# WKUP_j7aen_wkup_ctrl_mmr0_CFG0 register map
Vendor: Texas Instruments
Registers are 32-bit, read-write, reset 0x0 unless marked. A register's access mark holds for its fields unless they carry their own. Offsets are as the file gives them; [hi:lo] are bit positions; {n}, {i} and the like mark numbered series.

## WKUP_j7aen_wkup_ctrl_mmr0_CFG0 (part 2 of 3)
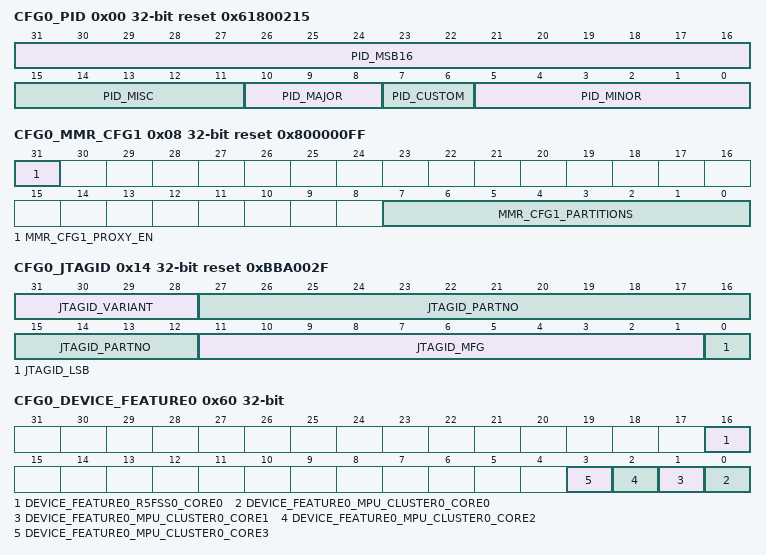
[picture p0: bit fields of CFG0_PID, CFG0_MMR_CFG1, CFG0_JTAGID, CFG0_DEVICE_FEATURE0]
0x00 CFG0_PID ro reset 0x61800215
  [31:16] PID_MSB16, [15:11] PID_MISC, [10:8] PID_MAJOR, [7:6] PID_CUSTOM, [5:0] PID_MINOR
0x08 CFG0_MMR_CFG1 ro reset 0x800000FF
  [31] MMR_CFG1_PROXY_EN — Proxy addressing activated
  [7:0] MMR_CFG1_PARTITIONS — Indicates present partitions
0x14 CFG0_JTAGID ro reset 0xBBA002F
  [31:28] JTAGID_VARIANT — Used to indicate new PGs
  [27:12] JTAGID_PARTNO — Part number for boundary scan
  [11:1] JTAGID_MFG — Indicates manufacturer
  [0] JTAGID_LSB — Always 1
0x18 CFG0_JTAG_USER_ID ro
  [31:0] JTAG_USER_ID_USERCODE — Device information
0x30 CFG0_MAIN_DEVSTAT
  [15:0] MAIN_DEVSTAT_BOOTMODE — Specifies the device Primary and Backup boot media.
0x34 CFG0_MAIN_BOOTCFG ro
  [15:0] MAIN_BOOTCFG_BOOTMODE — Specifies the device Primary and Backup boot media as latched at PORz
0x44 CFG0_BOOT_PROGRESS
  [31:0] BOOT_PROGRESS_PROGRESS — Written by ROM to indicate boot progression. Values and their meaning are determined by the ROM.
0x60 CFG0_DEVICE_FEATURE0 ro
  [16] DEVICE_FEATURE0_R5FSS0_CORE0 — Main R5FSS CPU0 Availability Field values (others are reserved): 1'b0 - NOT_AVAILABLE 1'b1 - AVAILABLE
  [n] DEVICE_FEATURE0_MPU_CLUSTER0_CORE{n} (n=0..3) — MPU Cluster0 Core {n} Availability Field values (others are reserved): 1'b0 - NOT_AVAILABLE 1'b1 - AVAILABLE
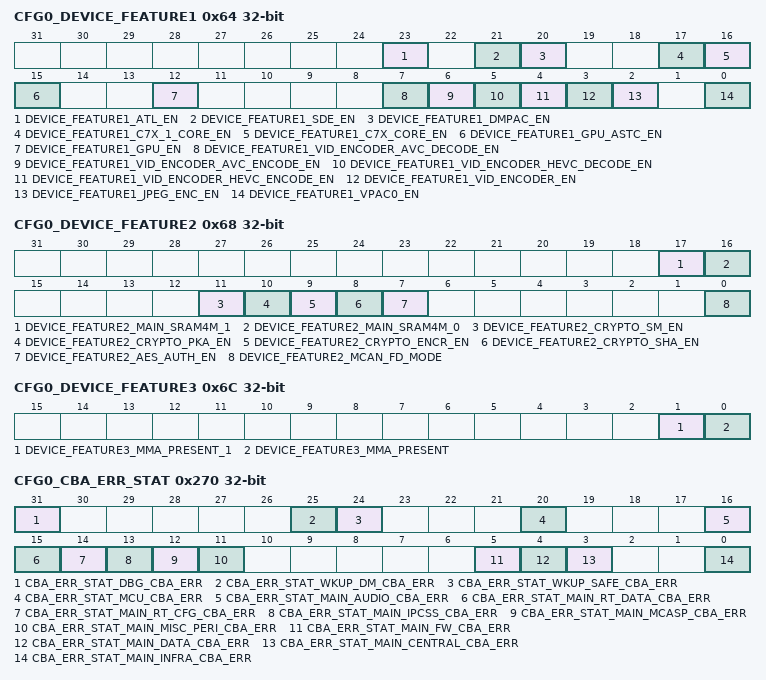
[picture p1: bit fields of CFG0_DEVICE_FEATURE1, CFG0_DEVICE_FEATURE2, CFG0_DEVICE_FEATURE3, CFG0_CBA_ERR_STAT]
0x64 CFG0_DEVICE_FEATURE1 ro
  [23] DEVICE_FEATURE1_ATL_EN — ATL Availability Field values (others are reserved): 1'b0 - NOT_AVAILABLE 1'b1 - AVAILABLE
  [21] DEVICE_FEATURE1_SDE_EN — DMPAC Stereo Disparity Engine is enabled when set Field values (others are reserved): 1'b0 - NOT_AVAILABLE 1'b1 - AVAILABLE
  [20] DEVICE_FEATURE1_DMPAC_EN — DMPAC is enabled when set Field values (others are reserved): 1'b0 - NOT_AVAILABLE 1'b1 - AVAILABLE
  [17] DEVICE_FEATURE1_C7X_1_CORE_EN — C7x1 Availability Field values (others are reserved): 1'b0 - NOT_AVAILABLE 1'b1 - AVAILABLE
  [16] DEVICE_FEATURE1_C7X_CORE_EN — C7x0 Availability Field values (others are reserved): 1'b0 - NOT_AVAILABLE 1'b1 - AVAILABLE
  [15] DEVICE_FEATURE1_GPU_ASTC_EN — GPU Adaptive Scalable Texture Compression Availability Field values (others are reserved): 1'b0 - NOT_AVAILABLE 1'b1 - AVAILABLE
  [12] DEVICE_FEATURE1_GPU_EN — GPU Availability Field values (others are reserved): 1'b0 - NOT_AVAILABLE 1'b1 - AVAILABLE
  [7] DEVICE_FEATURE1_VID_ENCODER_AVC_DECODE_EN — Video CODEC HEVC decode feature Availability Field values (others are reserved): 1'b0 - NOT_AVAILABLE 1'b1 - AVAILABLE
  [6] DEVICE_FEATURE1_VID_ENCODER_AVC_ENCODE_EN — Video CODEC HEVC encode feature Availability Field values (others are reserved): 1'b0 - NOT_AVAILABLE 1'b1 - AVAILABLE
  [5] DEVICE_FEATURE1_VID_ENCODER_HEVC_DECODE_EN — Video CODEC AVC decode feature Availability Field values (others are reserved): 1'b0 - NOT_AVAILABLE 1'b1 - AVAILABLE
  [4] DEVICE_FEATURE1_VID_ENCODER_HEVC_ENCODE_EN — Video CODEC AVC encode feature Availability Field values (others are reserved): 1'b0 - NOT_AVAILABLE 1'b1 - AVAILABLE
  [3] DEVICE_FEATURE1_VID_ENCODER_EN — Video CODEC Availability Field values (others are reserved): 1'b0 - NOT_AVAILABLE 1'b1 - AVAILABLE
  [2] DEVICE_FEATURE1_JPEG_ENC_EN — JPEG Encoder Availability Field values (others are reserved): 1'b0 - NOT_AVAILABLE 1'b1 - AVAILABLE
  [0] DEVICE_FEATURE1_VPAC0_EN — VPAC0 Availability Field values (others are reserved): 1'b0 - NOT_AVAILABLE 1'b1 - AVAILABLE
0x68 CFG0_DEVICE_FEATURE2 ro
  [17] DEVICE_FEATURE2_MAIN_SRAM4M_1 — Availability of Main SRAM 4M Bank 1 Field values (others are reserved): 1'b0 - NOT_AVAILABLE 1'b1 - AVAILABLE
  [16] DEVICE_FEATURE2_MAIN_SRAM4M_0 — Availability of Main SRAM 4M Bank 0 Field values (others are reserved): 1'b0 - NOT_AVAILABLE 1'b1 - AVAILABLE
  [11] DEVICE_FEATURE2_CRYPTO_SM_EN — SA3SS Crypto Module SM2, SM3, SM4 Availability Field values (others are reserved): 1'b0 - NOT_AVAILABLE 1'b1 - AVAILABLE
  [10] DEVICE_FEATURE2_CRYPTO_PKA_EN — SA3SS Crypto Module PKA Availability Field values (others are reserved): 1'b0 - NOT_AVAILABLE 1'b1 - AVAILABLE
  [9] DEVICE_FEATURE2_CRYPTO_ENCR_EN — SA3SS Crypto Module AES/3DES/DBRG Availability Field values (others are reserved): 1'b0 - NOT_AVAILABLE 1'b1 - AVAILABLE
  [8] DEVICE_FEATURE2_CRYPTO_SHA_EN — SA3SS Crypto Module SHA/MD5 Availability Field values (others are reserved): 1'b0 - NOT_AVAILABLE 1'b1 - AVAILABLE
  [7] DEVICE_FEATURE2_AES_AUTH_EN — AES authentication availability in FlashSS and SMS Field values (others are reserved): 1'b0 - NOT_AVAILABLE 1'b1 - AVAILABLE
  [0] DEVICE_FEATURE2_MCAN_FD_MODE — FD mode availability (applies to all MCAN instances) Field values (others are reserved): 1'b0 - NOT_AVAILABLE 1'b1 - AVAILABLE
0x6C CFG0_DEVICE_FEATURE3 ro
  [1] DEVICE_FEATURE3_MMA_PRESENT_1 — C7x1 MMA Feature Availability Field values (others are reserved): 1'b0 - NOT_AVAILABLE 1'b1 - AVAILABLE
  [0] DEVICE_FEATURE3_MMA_PRESENT — C7x0 MMA Feature Availability Field values (others are reserved): 1'b0 - NOT_AVAILABLE 1'b1 - AVAILABLE
0x78 CFG0_DEVICE_FEATURE6 ro
  [5] DEVICE_FEATURE6_SA3_UL — SA3SS domain security accelerator availability Field values (others are reserved): 1'b0 - NOT_AVAILABLE 1'b1 - AVAILABLE
0x200 CFG0_MAC_ID0
  [31:0] MAC_ID0_MACID_LO — 32 lsbs of MAC address
0x204 CFG0_MAC_ID1
  [15:0] MAC_ID1_MACID_HI — 16 msbs of MAC address
0x210 CFG0_PCI_DEVICE_ID0 reset 0xB010104C
  [31:0] PCI_DEVICE_ID0_ID0 — ROM writes 32-bit Value from Customer OTP to Here
0x214 CFG0_PCI_DEVICE_ID1 reset 0xB010104C
  [31:0] PCI_DEVICE_ID1_ID1 — ROM writes 32-bit Value from Customer OTP to Here
0x220 CFG0_USB_DEVICE_ID0 reset 0x61650451
  [31:0] USB_DEVICE_ID0_ID0 — ROM writes 32-bit Value from Customer OTP to Here
0x224 CFG0_USB_DEVICE_ID1 reset 0x61650451
  [31:0] USB_DEVICE_ID1_ID1 — ROM writes 32-bit Value from Customer OTP to Here
{0x230+4i} CFG0_GP_SW{i} ro (i=0..2)
  [31:0] GP_SW{i}_VAL — general purpose value
0x23C CFG0_GP_SW3 ro
  [3:0] GP_SW3_VAL — general purpose value
0x270 CFG0_CBA_ERR_STAT ro
  [31] CBA_ERR_STAT_DBG_CBA_ERR — Access Error from Main Debug CBASS Field values (others are reserved): 1'b0 - INACTIVE 1'b1 - ACTIVE
  [25] CBA_ERR_STAT_WKUP_DM_CBA_ERR — Access Error from Wkup Device Manager CBASS Field values (others are reserved): 1'b0 - INACTIVE 1'b1 - ACTIVE
  [24] CBA_ERR_STAT_WKUP_SAFE_CBA_ERR — Access Error from Wkup Safe CBASS Field values (others are reserved): 1'b0 - INACTIVE 1'b1 - ACTIVE
  [20] CBA_ERR_STAT_MCU_CBA_ERR — Access Error from MCU CBASS Field values (others are reserved): 1'b0 - INACTIVE 1'b1 - ACTIVE
  [16] CBA_ERR_STAT_MAIN_AUDIO_CBA_ERR — Access Error from Main Audio CBASS Field values (others are reserved): 1'b0 - INACTIVE 1'b1 - ACTIVE
  [15] CBA_ERR_STAT_MAIN_RT_DATA_CBA_ERR — Access Error from Main RT DATA CBASS Field values (others are reserved): 1'b0 - INACTIVE 1'b1 - ACTIVE
  [14] CBA_ERR_STAT_MAIN_RT_CFG_CBA_ERR — Access Error from Main RT CFG CBASS Field values (others are reserved): 1'b0 - INACTIVE 1'b1 - ACTIVE
  [13] CBA_ERR_STAT_MAIN_IPCSS_CBA_ERR — Access Error from Main IPCSS CBASS Field values (others are reserved): 1'b0 - INACTIVE 1'b1 - ACTIVE
  [12] CBA_ERR_STAT_MAIN_MCASP_CBA_ERR — Access Error from Main McASP CBASS Field values (others are reserved): 1'b0 - INACTIVE 1'b1 - ACTIVE
  [11] CBA_ERR_STAT_MAIN_MISC_PERI_CBA_ERR — Access Errror from Main Misc. Peripheral CBASS Field values (others are reserved): 1'b0 - INACTIVE 1'b1 - ACTIVE
  [5] CBA_ERR_STAT_MAIN_FW_CBA_ERR — Access Error from Main Firewall CBASS Field values (others are reserved): 1'b0 - INACTIVE 1'b1 - ACTIVE
  [4] CBA_ERR_STAT_MAIN_DATA_CBA_ERR — Access Error from Main Data CBASS Field values (others are reserved): 1'b0 - INACTIVE 1'b1 - ACTIVE
  [3] CBA_ERR_STAT_MAIN_CENTRAL_CBA_ERR — Access Error from Main Central CBASS Field values (others are reserved): 1'b0 - INACTIVE 1'b1 - ACTIVE
  [0] CBA_ERR_STAT_MAIN_INFRA_CBA_ERR — Access Error from Main Infrastructure CBASS Field values (others are reserved): 1'b0 - INACTIVE 1'b1 - ACTIVE
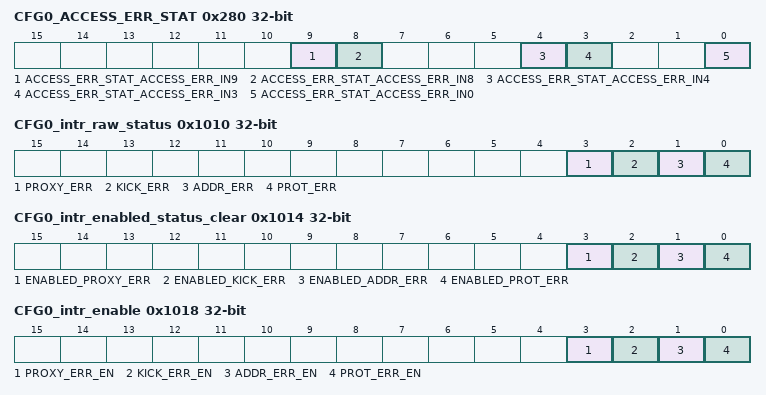
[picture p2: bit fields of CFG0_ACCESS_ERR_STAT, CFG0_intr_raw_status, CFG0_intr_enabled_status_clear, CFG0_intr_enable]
0x280 CFG0_ACCESS_ERR_STAT ro
  [9] ACCESS_ERR_STAT_ACCESS_ERR_IN9 — Access Error Detected in MCU PadCfg MMR Field values (others are reserved): 1'b0 - INACTIVE 1'b1 - ACTIVE
  [8] ACCESS_ERR_STAT_ACCESS_ERR_IN8 — Access Error Detected in MCU Ctrl MMR Field values (others are reserved): 1'b0 - INACTIVE 1'b1 - ACTIVE
  [4] ACCESS_ERR_STAT_ACCESS_ERR_IN4 — Access Error Detected in MAIN PadCfg MMR Field values (others are reserved): 1'b0 - INACTIVE 1'b1 - ACTIVE
  [3] ACCESS_ERR_STAT_ACCESS_ERR_IN3 — Access Error Detected in MAIN Ctrl MMR Field values (others are reserved): 1'b0 - INACTIVE 1'b1 - ACTIVE
  [0] ACCESS_ERR_STAT_ACCESS_ERR_IN0 — Access Error Detected in WKUP Ctrl MMR Field values (others are reserved): 1'b0 - INACTIVE 1'b1 - ACTIVE
{0x1008+0x4000*i} CFG0_LOCK{i}_KICK0 (i=0..7)
  [31:0] LOCK{i}_KICK0 — - KICK0 component
{0x100C+0x4000*i} CFG0_LOCK{i}_KICK1 (i=0..7)
  [31:0] LOCK{i}_KICK1 — - KICK1 component
0x1010 CFG0_intr_raw_status access not given
  [3] PROXY_ERR — Proxy0 access violation error. Raw status is read. Write a 1 to set the status. Writing a 0 has no effect. (access R/W1TS)
  [2] KICK_ERR — Kick access violation error. Raw status is read. Write a 1 to set the status. Writing a 0 has no effect. (access R/W1TS)
  [1] ADDR_ERR — Addressing violation error. Raw status is read. Write a 1 to set the status. Writing a 0 has no effect. (access R/W1TS)
  [0] PROT_ERR — Protection violation error. Raw status is read. Write a 1 to set the status. Writing a 0 has no effect. (access R/W1TS)
0x1014 CFG0_intr_enabled_status_clear access not given
  [3] ENABLED_PROXY_ERR — Proxy0 access violation error. Enabled status is read. Write a 1 to clear the status. Writing a 0 has no effect. (access R/W1TC)
  [2] ENABLED_KICK_ERR — Kick access violation error. Enabled status is read. Write a 1 to clear the status. Writing a 0 has no effect. (access R/W1TC)
  [1] ENABLED_ADDR_ERR — Addressing violation error. Enabled status is read. Write a 1 to clear the status. Writing a 0 has no effect. (access R/W1TC)
  [0] ENABLED_PROT_ERR — Protection violation error. Enabled status is read. Write a 1 to clear the status. Writing a 0 has no effect. (access R/W1TC)
0x1018 CFG0_intr_enable access not given
  [3] PROXY_ERR_EN — Proxy0 access violation error enable. Write a 1 to set the enable. Writing a 0 has no effect. (access R/W1TS)
  [2] KICK_ERR_EN — Kick access violation error enable. Write a 1 to set the enable. Writing a 0 has no effect. (access R/W1TS)
  [1] ADDR_ERR_EN — Addressing violation error enable. Write a 1 to set the enable. Writing a 0 has no effect. (access R/W1TS)
  [0] PROT_ERR_EN — Protection violation error enable. Write a 1 to set the enable. Writing a 0 has no effect. (access R/W1TS)
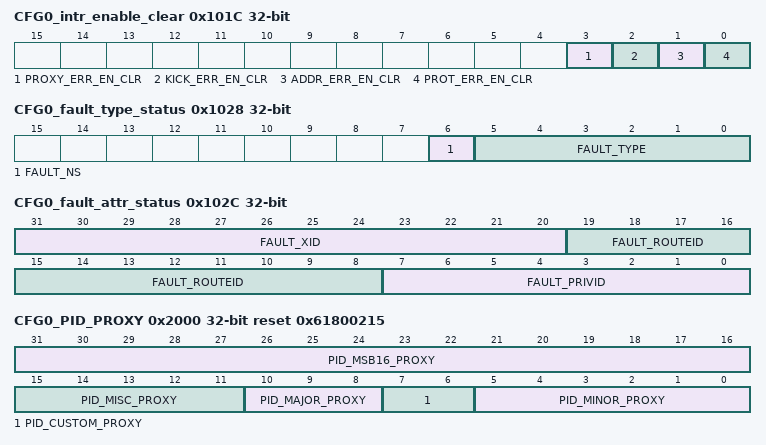
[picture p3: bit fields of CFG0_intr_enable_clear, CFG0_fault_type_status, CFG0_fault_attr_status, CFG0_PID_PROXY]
0x101C CFG0_intr_enable_clear access not given
  [3] PROXY_ERR_EN_CLR — Proxy0 access violation error enable clear. Write a 1 to clear the enable. Writing a 0 has no effect. (access R/W1TC)
  [2] KICK_ERR_EN_CLR — Kick access violation error enable clear. Write a 1 to clear the enable. Writing a 0 has no effect. (access R/W1TC)
  [1] ADDR_ERR_EN_CLR — Addressing violation error enable clear. Write a 1 to clear the enable. Writing a 0 has no effect. (access R/W1TC)
  [0] PROT_ERR_EN_CLR — Protection violation error enable clear. Write a 1 to clear the enable. Writing a 0 has no effect. (access R/W1TC)
0x1020 CFG0_eoi
  [7:0] EOI_VECTOR — EOI vector value. Write this with interrupt distribution value in the chip.
0x1024 CFG0_fault_address ro
  [31:0] FAULT_ADDR — Fault Address.
0x1028 CFG0_fault_type_status ro
  [6] FAULT_NS — Non-secure access.
  [5:0] FAULT_TYPE — Fault Type 10_0000 = Supervisor read fault - priv = 1 dir = 1 dtype != 1 01_0000 = Supervisor write fault - priv = 1 dir = 0 00_1000 = Supervisor execute fault - priv = 1 dir = 1 dtype = 1 00_0100 = User read fault - priv = 0 dir = 1 dtype = 1 00_0010 = User write fault - priv = 0 dir = 0 00_0001 = User execute fault - priv = 0 dir = 1 dtype = 1 00_0000 = No fault
0x102C CFG0_fault_attr_status ro
  [31:20] FAULT_XID — XID.
  [19:8] FAULT_ROUTEID — Route ID.
  [7:0] FAULT_PRIVID — Privilege ID.
0x1030 CFG0_fault_clear wo
  [0] FAULT_CLR — Fault clear. Writing a 1 clears the current fault. Writing a 0 has no effect.
{0x1100+4i} CFG0_CLAIMREG_P0_R{i}_READONLY ro (i=0..6)
  [31:0] CLAIMREG_P0_R{i}_READONLY — Claim bits for Partition 0
0x2000 CFG0_PID_PROXY ro reset 0x61800215
  [31:16] PID_MSB16_PROXY, [15:11] PID_MISC_PROXY, [10:8] PID_MAJOR_PROXY, [7:6] PID_CUSTOM_PROXY, [5:0] PID_MINOR_PROXY
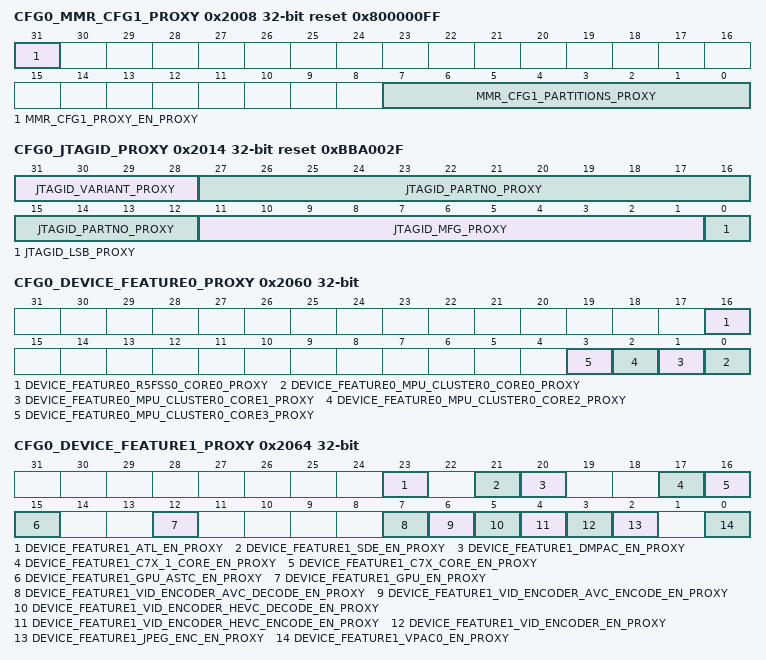
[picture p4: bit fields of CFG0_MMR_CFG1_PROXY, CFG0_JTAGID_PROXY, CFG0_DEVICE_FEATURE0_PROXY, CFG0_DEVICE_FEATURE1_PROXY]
0x2008 CFG0_MMR_CFG1_PROXY ro reset 0x800000FF
  [31] MMR_CFG1_PROXY_EN_PROXY — Proxy addressing activated
  [7:0] MMR_CFG1_PARTITIONS_PROXY — Indicates present partitions
0x2014 CFG0_JTAGID_PROXY ro reset 0xBBA002F
  [31:28] JTAGID_VARIANT_PROXY — Used to indicate new PGs
  [27:12] JTAGID_PARTNO_PROXY — Part number for boundary scan
  [11:1] JTAGID_MFG_PROXY — Indicates manufacturer
  [0] JTAGID_LSB_PROXY — Always 1
0x2018 CFG0_JTAG_USER_ID_PROXY ro
  [31:0] JTAG_USER_ID_USERCODE_PROXY — Device information
0x2030 CFG0_MAIN_DEVSTAT_PROXY
  [15:0] MAIN_DEVSTAT_BOOTMODE_PROXY — Specifies the device Primary and Backup boot media.
0x2034 CFG0_MAIN_BOOTCFG_PROXY ro
  [15:0] MAIN_BOOTCFG_BOOTMODE_PROXY — Specifies the device Primary and Backup boot media as latched at PORz
0x2044 CFG0_BOOT_PROGRESS_PROXY
  [31:0] BOOT_PROGRESS_PROGRESS_PROXY — Written by ROM to indicate boot progression. Values and their meaning are determined by the ROM.
0x2060 CFG0_DEVICE_FEATURE0_PROXY ro
  [16] DEVICE_FEATURE0_R5FSS0_CORE0_PROXY — Main R5FSS CPU0 Availability Field values (others are reserved): 1'b0 - NOT_AVAILABLE 1'b1 - AVAILABLE
  [n] DEVICE_FEATURE0_MPU_CLUSTER0_CORE{n}_PROXY (n=0..3) — MPU Cluster0 Core {n} Availability Field values (others are reserved): 1'b0 - NOT_AVAILABLE 1'b1 - AVAILABLE
0x2064 CFG0_DEVICE_FEATURE1_PROXY ro
  [23] DEVICE_FEATURE1_ATL_EN_PROXY — ATL Availability Field values (others are reserved): 1'b0 - NOT_AVAILABLE 1'b1 - AVAILABLE
  [21] DEVICE_FEATURE1_SDE_EN_PROXY — DMPAC Stereo Disparity Engine is enabled when set Field values (others are reserved): 1'b0 - NOT_AVAILABLE 1'b1 - AVAILABLE
  [20] DEVICE_FEATURE1_DMPAC_EN_PROXY — DMPAC is enabled when set Field values (others are reserved): 1'b0 - NOT_AVAILABLE 1'b1 - AVAILABLE
  [17] DEVICE_FEATURE1_C7X_1_CORE_EN_PROXY — C7x1 Availability Field values (others are reserved): 1'b0 - NOT_AVAILABLE 1'b1 - AVAILABLE
  [16] DEVICE_FEATURE1_C7X_CORE_EN_PROXY — C7x0 Availability Field values (others are reserved): 1'b0 - NOT_AVAILABLE 1'b1 - AVAILABLE
  [15] DEVICE_FEATURE1_GPU_ASTC_EN_PROXY — GPU Adaptive Scalable Texture Compression Availability Field values (others are reserved): 1'b0 - NOT_AVAILABLE 1'b1 - AVAILABLE
  [12] DEVICE_FEATURE1_GPU_EN_PROXY — GPU Availability Field values (others are reserved): 1'b0 - NOT_AVAILABLE 1'b1 - AVAILABLE
  [7] DEVICE_FEATURE1_VID_ENCODER_AVC_DECODE_EN_PROXY — Video CODEC HEVC decode feature Availability Field values (others are reserved): 1'b0 - NOT_AVAILABLE 1'b1 - AVAILABLE
  [6] DEVICE_FEATURE1_VID_ENCODER_AVC_ENCODE_EN_PROXY — Video CODEC HEVC encode feature Availability Field values (others are reserved): 1'b0 - NOT_AVAILABLE 1'b1 - AVAILABLE
  [5] DEVICE_FEATURE1_VID_ENCODER_HEVC_DECODE_EN_PROXY — Video CODEC AVC decode feature Availability Field values (others are reserved): 1'b0 - NOT_AVAILABLE 1'b1 - AVAILABLE
  [4] DEVICE_FEATURE1_VID_ENCODER_HEVC_ENCODE_EN_PROXY — Video CODEC AVC encode feature Availability Field values (others are reserved): 1'b0 - NOT_AVAILABLE 1'b1 - AVAILABLE
  [3] DEVICE_FEATURE1_VID_ENCODER_EN_PROXY — Video CODEC Availability Field values (others are reserved): 1'b0 - NOT_AVAILABLE 1'b1 - AVAILABLE
  [2] DEVICE_FEATURE1_JPEG_ENC_EN_PROXY — JPEG Encoder Availability Field values (others are reserved): 1'b0 - NOT_AVAILABLE 1'b1 - AVAILABLE
  [0] DEVICE_FEATURE1_VPAC0_EN_PROXY — VPAC0 Availability Field values (others are reserved): 1'b0 - NOT_AVAILABLE 1'b1 - AVAILABLE
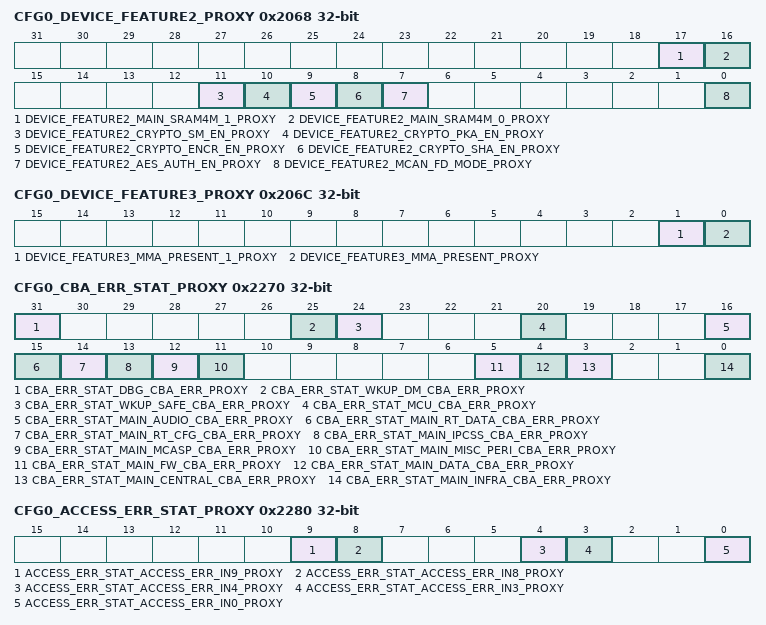
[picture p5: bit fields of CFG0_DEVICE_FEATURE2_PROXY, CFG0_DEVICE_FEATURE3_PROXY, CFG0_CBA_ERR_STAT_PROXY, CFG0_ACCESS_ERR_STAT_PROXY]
0x2068 CFG0_DEVICE_FEATURE2_PROXY ro
  [17] DEVICE_FEATURE2_MAIN_SRAM4M_1_PROXY — Availability of Main SRAM 4M Bank 1 Field values (others are reserved): 1'b0 - NOT_AVAILABLE 1'b1 - AVAILABLE
  [16] DEVICE_FEATURE2_MAIN_SRAM4M_0_PROXY — Availability of Main SRAM 4M Bank 0 Field values (others are reserved): 1'b0 - NOT_AVAILABLE 1'b1 - AVAILABLE
  [11] DEVICE_FEATURE2_CRYPTO_SM_EN_PROXY — SA3SS Crypto Module SM2, SM3, SM4 Availability Field values (others are reserved): 1'b0 - NOT_AVAILABLE 1'b1 - AVAILABLE
  [10] DEVICE_FEATURE2_CRYPTO_PKA_EN_PROXY — SA3SS Crypto Module PKA Availability Field values (others are reserved): 1'b0 - NOT_AVAILABLE 1'b1 - AVAILABLE
  [9] DEVICE_FEATURE2_CRYPTO_ENCR_EN_PROXY — SA3SS Crypto Module AES/3DES/DBRG Availability Field values (others are reserved): 1'b0 - NOT_AVAILABLE 1'b1 - AVAILABLE
  [8] DEVICE_FEATURE2_CRYPTO_SHA_EN_PROXY — SA3SS Crypto Module SHA/MD5 Availability Field values (others are reserved): 1'b0 - NOT_AVAILABLE 1'b1 - AVAILABLE
  [7] DEVICE_FEATURE2_AES_AUTH_EN_PROXY — AES authentication availability in FlashSS and SMS Field values (others are reserved): 1'b0 - NOT_AVAILABLE 1'b1 - AVAILABLE
  [0] DEVICE_FEATURE2_MCAN_FD_MODE_PROXY — FD mode availability (applies to all MCAN instances) Field values (others are reserved): 1'b0 - NOT_AVAILABLE 1'b1 - AVAILABLE
0x206C CFG0_DEVICE_FEATURE3_PROXY ro
  [1] DEVICE_FEATURE3_MMA_PRESENT_1_PROXY — C7x1 MMA Feature Availability Field values (others are reserved): 1'b0 - NOT_AVAILABLE 1'b1 - AVAILABLE
  [0] DEVICE_FEATURE3_MMA_PRESENT_PROXY — C7x0 MMA Feature Availability Field values (others are reserved): 1'b0 - NOT_AVAILABLE 1'b1 - AVAILABLE
0x2078 CFG0_DEVICE_FEATURE6_PROXY ro
  [5] DEVICE_FEATURE6_SA3_UL_PROXY — SA3SS domain security accelerator availability Field values (others are reserved): 1'b0 - NOT_AVAILABLE 1'b1 - AVAILABLE
0x2200 CFG0_MAC_ID0_PROXY
  [31:0] MAC_ID0_MACID_LO_PROXY — 32 lsbs of MAC address
0x2204 CFG0_MAC_ID1_PROXY
  [15:0] MAC_ID1_MACID_HI_PROXY — 16 msbs of MAC address
0x2210 CFG0_PCI_DEVICE_ID0_PROXY reset 0xB010104C
  [31:0] PCI_DEVICE_ID0_ID0_PROXY — ROM writes 32-bit Value from Customer OTP to Here
0x2214 CFG0_PCI_DEVICE_ID1_PROXY reset 0xB010104C
  [31:0] PCI_DEVICE_ID1_ID1_PROXY — ROM writes 32-bit Value from Customer OTP to Here
0x2220 CFG0_USB_DEVICE_ID0_PROXY reset 0x61650451
  [31:0] USB_DEVICE_ID0_ID0_PROXY — ROM writes 32-bit Value from Customer OTP to Here
0x2224 CFG0_USB_DEVICE_ID1_PROXY reset 0x61650451
  [31:0] USB_DEVICE_ID1_ID1_PROXY — ROM writes 32-bit Value from Customer OTP to Here
{0x2230+4i} CFG0_GP_SW{i}_PROXY ro (i=0..2)
  [31:0] GP_SW{i}_VAL_PROXY — general purpose value
0x223C CFG0_GP_SW3_PROXY ro
  [3:0] GP_SW3_VAL_PROXY — general purpose value
0x2270 CFG0_CBA_ERR_STAT_PROXY ro
  [31] CBA_ERR_STAT_DBG_CBA_ERR_PROXY — Access Error from Main Debug CBASS Field values (others are reserved): 1'b0 - INACTIVE 1'b1 - ACTIVE
  [25] CBA_ERR_STAT_WKUP_DM_CBA_ERR_PROXY — Access Error from Wkup Device Manager CBASS Field values (others are reserved): 1'b0 - INACTIVE 1'b1 - ACTIVE
  [24] CBA_ERR_STAT_WKUP_SAFE_CBA_ERR_PROXY — Access Error from Wkup Safe CBASS Field values (others are reserved): 1'b0 - INACTIVE 1'b1 - ACTIVE
  [20] CBA_ERR_STAT_MCU_CBA_ERR_PROXY — Access Error from MCU CBASS Field values (others are reserved): 1'b0 - INACTIVE 1'b1 - ACTIVE
  [16] CBA_ERR_STAT_MAIN_AUDIO_CBA_ERR_PROXY — Access Error from Main Audio CBASS Field values (others are reserved): 1'b0 - INACTIVE 1'b1 - ACTIVE
  [15] CBA_ERR_STAT_MAIN_RT_DATA_CBA_ERR_PROXY — Access Error from Main RT DATA CBASS Field values (others are reserved): 1'b0 - INACTIVE 1'b1 - ACTIVE
  [14] CBA_ERR_STAT_MAIN_RT_CFG_CBA_ERR_PROXY — Access Error from Main RT CFG CBASS Field values (others are reserved): 1'b0 - INACTIVE 1'b1 - ACTIVE
  [13] CBA_ERR_STAT_MAIN_IPCSS_CBA_ERR_PROXY — Access Error from Main IPCSS CBASS Field values (others are reserved): 1'b0 - INACTIVE 1'b1 - ACTIVE
  [12] CBA_ERR_STAT_MAIN_MCASP_CBA_ERR_PROXY — Access Error from Main McASP CBASS Field values (others are reserved): 1'b0 - INACTIVE 1'b1 - ACTIVE
  [11] CBA_ERR_STAT_MAIN_MISC_PERI_CBA_ERR_PROXY — Access Errror from Main Misc. Peripheral CBASS Field values (others are reserved): 1'b0 - INACTIVE 1'b1 - ACTIVE
  [5] CBA_ERR_STAT_MAIN_FW_CBA_ERR_PROXY — Access Error from Main Firewall CBASS Field values (others are reserved): 1'b0 - INACTIVE 1'b1 - ACTIVE
  [4] CBA_ERR_STAT_MAIN_DATA_CBA_ERR_PROXY — Access Error from Main Data CBASS Field values (others are reserved): 1'b0 - INACTIVE 1'b1 - ACTIVE
  [3] CBA_ERR_STAT_MAIN_CENTRAL_CBA_ERR_PROXY — Access Error from Main Central CBASS Field values (others are reserved): 1'b0 - INACTIVE 1'b1 - ACTIVE
  [0] CBA_ERR_STAT_MAIN_INFRA_CBA_ERR_PROXY — Access Error from Main Infrastructure CBASS Field values (others are reserved): 1'b0 - INACTIVE 1'b1 - ACTIVE
0x2280 CFG0_ACCESS_ERR_STAT_PROXY ro
  [9] ACCESS_ERR_STAT_ACCESS_ERR_IN9_PROXY — Access Error Detected in MCU PadCfg MMR Field values (others are reserved): 1'b0 - INACTIVE 1'b1 - ACTIVE
  [8] ACCESS_ERR_STAT_ACCESS_ERR_IN8_PROXY — Access Error Detected in MCU Ctrl MMR Field values (others are reserved): 1'b0 - INACTIVE 1'b1 - ACTIVE
  [4] ACCESS_ERR_STAT_ACCESS_ERR_IN4_PROXY — Access Error Detected in MAIN PadCfg MMR Field values (others are reserved): 1'b0 - INACTIVE 1'b1 - ACTIVE
  [3] ACCESS_ERR_STAT_ACCESS_ERR_IN3_PROXY — Access Error Detected in MAIN Ctrl MMR Field values (others are reserved): 1'b0 - INACTIVE 1'b1 - ACTIVE
  [0] ACCESS_ERR_STAT_ACCESS_ERR_IN0_PROXY — Access Error Detected in WKUP Ctrl MMR Field values (others are reserved): 1'b0 - INACTIVE 1'b1 - ACTIVE
{0x3008+0x4000*i} CFG0_LOCK{i}_KICK0_PROXY (i=0..7)
  [31:0] LOCK{i}_KICK0_PROXY — - KICK0 component
{0x300C+0x4000*i} CFG0_LOCK{i}_KICK1_PROXY (i=0..7)
  [31:0] LOCK{i}_KICK1_PROXY — - KICK1 component
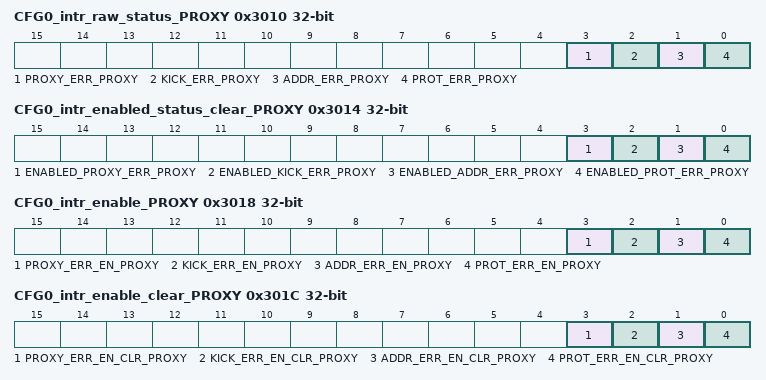
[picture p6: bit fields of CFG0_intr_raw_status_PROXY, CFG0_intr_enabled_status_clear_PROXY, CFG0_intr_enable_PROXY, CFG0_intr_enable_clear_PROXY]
0x3010 CFG0_intr_raw_status_PROXY access not given
  [3] PROXY_ERR_PROXY — Proxy0 access violation error. Raw status is read. Write a 1 to set the status. Writing a 0 has no effect. (access R/W1TS)
  [2] KICK_ERR_PROXY — Kick access violation error. Raw status is read. Write a 1 to set the status. Writing a 0 has no effect. (access R/W1TS)
  [1] ADDR_ERR_PROXY — Addressing violation error. Raw status is read. Write a 1 to set the status. Writing a 0 has no effect. (access R/W1TS)
  [0] PROT_ERR_PROXY — Protection violation error. Raw status is read. Write a 1 to set the status. Writing a 0 has no effect. (access R/W1TS)
0x3014 CFG0_intr_enabled_status_clear_PROXY access not given
  [3] ENABLED_PROXY_ERR_PROXY — Proxy0 access violation error. Enabled status is read. Write a 1 to clear the status. Writing a 0 has no effect. (access R/W1TC)
  [2] ENABLED_KICK_ERR_PROXY — Kick access violation error. Enabled status is read. Write a 1 to clear the status. Writing a 0 has no effect. (access R/W1TC)
  [1] ENABLED_ADDR_ERR_PROXY — Addressing violation error. Enabled status is read. Write a 1 to clear the status. Writing a 0 has no effect. (access R/W1TC)
  [0] ENABLED_PROT_ERR_PROXY — Protection violation error. Enabled status is read. Write a 1 to clear the status. Writing a 0 has no effect. (access R/W1TC)
0x3018 CFG0_intr_enable_PROXY access not given
  [3] PROXY_ERR_EN_PROXY — Proxy0 access violation error enable. Write a 1 to set the enable. Writing a 0 has no effect. (access R/W1TS)
  [2] KICK_ERR_EN_PROXY — Kick access violation error enable. Write a 1 to set the enable. Writing a 0 has no effect. (access R/W1TS)
  [1] ADDR_ERR_EN_PROXY — Addressing violation error enable. Write a 1 to set the enable. Writing a 0 has no effect. (access R/W1TS)
  [0] PROT_ERR_EN_PROXY — Protection violation error enable. Write a 1 to set the enable. Writing a 0 has no effect. (access R/W1TS)
0x301C CFG0_intr_enable_clear_PROXY access not given
  [3] PROXY_ERR_EN_CLR_PROXY — Proxy0 access violation error enable clear. Write a 1 to clear the enable. Writing a 0 has no effect. (access R/W1TC)
  [2] KICK_ERR_EN_CLR_PROXY — Kick access violation error enable clear. Write a 1 to clear the enable. Writing a 0 has no effect. (access R/W1TC)
  [1] ADDR_ERR_EN_CLR_PROXY — Addressing violation error enable clear. Write a 1 to clear the enable. Writing a 0 has no effect. (access R/W1TC)
  [0] PROT_ERR_EN_CLR_PROXY — Protection violation error enable clear. Write a 1 to clear the enable. Writing a 0 has no effect. (access R/W1TC)
0x3020 CFG0_eoi_PROXY
  [7:0] EOI_VECTOR_PROXY — EOI vector value. Write this with interrupt distribution value in the chip.
0x3024 CFG0_fault_address_PROXY ro
  [31:0] FAULT_ADDR_PROXY — Fault Address.
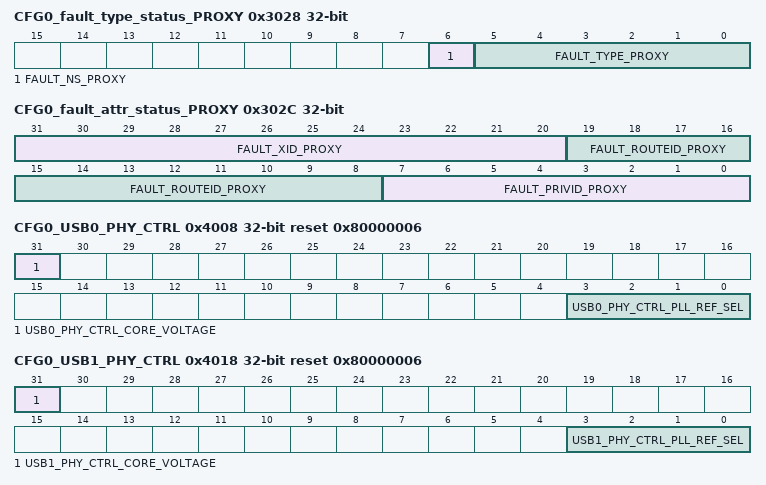
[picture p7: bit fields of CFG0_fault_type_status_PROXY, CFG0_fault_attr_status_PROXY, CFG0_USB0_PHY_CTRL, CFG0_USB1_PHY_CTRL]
0x3028 CFG0_fault_type_status_PROXY ro
  [6] FAULT_NS_PROXY — Non-secure access.
  [5:0] FAULT_TYPE_PROXY — Fault Type 10_0000 = Supervisor read fault - priv = 1 dir = 1 dtype != 1 01_0000 = Supervisor write fault - priv = 1 dir = 0 00_1000 = Supervisor execute fault - priv = 1 dir = 1 dtype = 1 00_0100 = User read fault - priv = 0 dir = 1 dtype = 1 00_0010 = User write fault - priv = 0 dir = 0 00_0001 = User execute fault - priv = 0 dir = 1 dtype = 1 00_0000 = No fault
0x302C CFG0_fault_attr_status_PROXY ro
  [31:20] FAULT_XID_PROXY — XID.
  [19:8] FAULT_ROUTEID_PROXY — Route ID.
  [7:0] FAULT_PRIVID_PROXY — Privilege ID.
0x3030 CFG0_fault_clear_PROXY wo
  [0] FAULT_CLR_PROXY — Fault clear. Writing a 1 clears the current fault. Writing a 0 has no effect.
{0x3100+4i} CFG0_CLAIMREG_P0_R{i} (i=0..6)
  [31:0] CLAIMREG_P0_R{i} — Claim bits for Partition 0
0x4008 CFG0_USB0_PHY_CTRL reset 0x80000006
  [31] USB0_PHY_CTRL_CORE_VOLTAGE — Selects the USB PHY Core Voltage Option: 0.85V or 0.75/0.80V Field values (others are reserved): 1'b0 - V_0P85 1'b1 - V_0P75_0P80
  [3:0] USB0_PHY_CTRL_PLL_REF_SEL — Indicates the frequency of the REF_CLOCK input used by the USB PLL. This value should be set to match the frequency of the USB0 input clock, as selected by the USB0_CLKSEL register Field values (others are reserved): 4'b0000 - MHZ_9P6 4'b0001 - MHZ_10 4'b0010 - MHZ_12 4'b0011 - MHZ_19P2 4'b0100 - MHZ_20 4'b0101 - MHZ_24 4'b0110 - MHZ_25 4'b0111 - MHZ_26 4'b1000 - MHZ_38P4 4'b1001 - MHZ_40 4'b1010 - MHZ_48 4'b1011 - MHZ_50 4'b1100 - MHZ_52
0x4018 CFG0_USB1_PHY_CTRL reset 0x80000006
  [31] USB1_PHY_CTRL_CORE_VOLTAGE — Selects the USB PHY Core Voltage Option: 0.85V or 0.75/0.80V Field values (others are reserved): 1'b0 - V_0P85 1'b1 - V_0P75_0P80
  [3:0] USB1_PHY_CTRL_PLL_REF_SEL — Indicates the frequency of the REF_CLOCK input used by the USB PLL. This value should be set to match the frequency of the USB1 input clock, as selected by the USB1_CLKSEL register Field values (others are reserved): 4'b0000 - MHZ_9P6 4'b0001 - MHZ_10 4'b0010 - MHZ_12 4'b0011 - MHZ_19P2 4'b0100 - MHZ_20 4'b0101 - MHZ_24 4'b0110 - MHZ_25 4'b0111 - MHZ_26 4'b1000 - MHZ_38P4 4'b1001 - MHZ_40 4'b1010 - MHZ_48 4'b1011 - MHZ_50 4'b1100 - MHZ_52
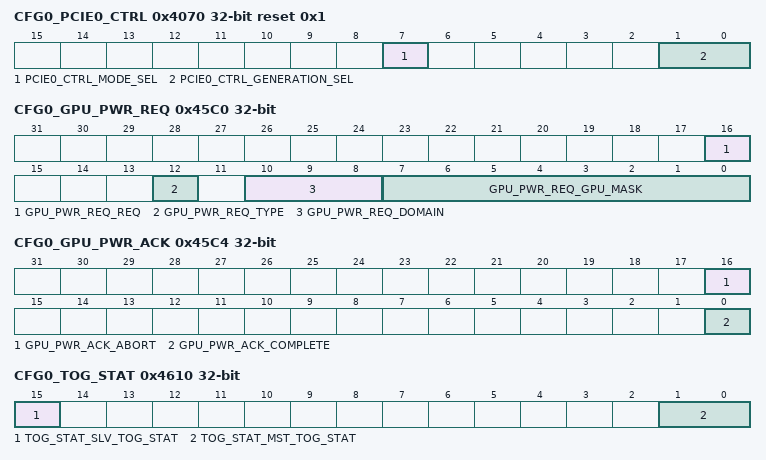
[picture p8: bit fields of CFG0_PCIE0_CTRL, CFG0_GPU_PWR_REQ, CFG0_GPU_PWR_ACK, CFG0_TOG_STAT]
0x4070 CFG0_PCIE0_CTRL reset 0x1
  [7] PCIE0_CTRL_MODE_SEL — Selects the operating mode Field values (others are reserved): 1'b0 - ENDPOINT 1'b1 - ROOT_COMPLEX
  [1:0] PCIE0_CTRL_GENERATION_SEL — Configures the PCIe generation support in the PCIe capabilities linked-list Field values (others are reserved): 2'b00 - GEN1 2'b01 - GEN2 2'b10 - GEN3
{0x41B4+4i} CFG0_SDIO{i}_CTRL (i=0..2)
  [4:0] SDIO{i}_CTRL_DRV_STR — Selects the SDIO drive strength Note: Values other than the reset value may invalidate the datasheet timing parameters and therefore should not be used.. Default is an efuse trimmed value, trimmed to aproximately 40 Ohms. Expected values for trim are between DS_10 and DS_19. Changing the value of this field is not recommended. Field values (others are reserved): 5'b11111 - DS_31 (MAX) 5'b11110 - DS_30 5'b11101 - DS_29 5'b11100 - DS_28 5'b11011 - DS_27 5'b11010 - DS_26 5'b11001 - DS_25 5'b11000 - DS_24 5'b10111 - DS_23 5'b10110 - DS_22 5'b10101 - DS_21 5'b10100 - DS_20 5'b10011 - DS_19 5'b10010 - DS_18 5'b10001 - DS_17 5'b10000 - DS_16 5'b01111 - DS_15 5'b01110 - DS_14 5'b01101 - DS_13 5'b01100 - DS_12 5'b01011 - DS_11 5'b01010 - DS_10 5'b01001 - DS_9 5'b01000 - DS_8 5'b00111 - DS_7 5'b00110 - DS_6 5'b00101 - DS_5 5'b00100 - DS_4 5'b00011 - DS_3 5'b00010 - DS_2 5'b00001 - DS_1 5'b00000 - DS_0 (MIN)
0x4204 CFG0_WKUP_TIMER1_CTRL
  [8] WKUP_TIMER1_CTRL_CASCADE_EN — Activates cascading of TIMER1 to TIMER0 Field values (others are reserved): 1'b0 - CASCADE_DEACTIVATED 1'b1 - CASCADE_ACTIVATED
0x42E0 CFG0_WKUP_I2C0_CTRL
  [0] WKUP_I2C0_CTRL_HS_MCS_EN — HS Mode controller current source activate. When set, activates the current-source pull-up on the SCL output. Only one controller on the I2C bus should activate SCL current sourcing. Field values (others are reserved): 1'b0 - HS_MCS_INACTIVE 1'b1 - HS_MCS_ACTIVE
0x45C0 CFG0_GPU_PWR_REQ ro
  [16] GPU_PWR_REQ_REQ — Power control request. This bit is set by the GPU to request a Power Management event to the PM processor. This will generate a gpu0_pwr_req interrupt. The interrupt is cleared only when the GPU clears its pwrctrl_gpu_req output. Field values (others are reserved): 1'b0 - CLEARED 1'b1 - POWER_REQ_ACTIVE
  [12] GPU_PWR_REQ_TYPE — GPU request type. Field values (others are reserved): 1'b0 - POWER_DOWN_REQ 1'b1 - POWER_UP_REQ
  [10:8] GPU_PWR_REQ_DOMAIN — GPU request mask. Indicates GPU domain to which the power event applies. For mapping refer to GPU RGX_CR_POWER_EVENT register.
  [7:0] GPU_PWR_REQ_GPU_MASK — GPU request mask. One bit per GPU indicating to which GPUs the power event applies. Mask bits are indexed by GPU_ID
0x45C4 CFG0_GPU_PWR_ACK
  [16] GPU_PWR_ACK_ABORT — Power control exit. This bit is set by the PM processor to that the GPU power control request could not be completed. The bit is cleared to 0 when gpu0_pwr_req goes low. Field values (others are reserved): 1'b0 - CLEARED 1'b1 - ERROR_NOT_COMPLETED
  [0] GPU_PWR_ACK_COMPLETE — Power control complete. This bit is set by the PM processor to indicate sucessful completion of the GPU power control request. The bit is cleared to 0 when gpu0_pwr_req goes low. Field values (others are reserved): 1'b0 - CLEARED 1'b1 - COMPLETE
0x4610 CFG0_TOG_STAT ro
  [15] TOG_STAT_SLV_TOG_STAT — Error Status of Target Timeout Gaskets Field values (others are reserved): 1'b0 - NONE 1'b1 - MCU_TIMEOUT0 (mcu2dm)
  [1:0] TOG_STAT_MST_TOG_STAT — Error Status of Target Timeout Gaskets Field values (others are reserved): 2'b00 - NONE 2'b01 - WKUP_TIMEOUT1 (dm2mcu) undefined - undefined 2'b10 - WKUP_TIMEOUT0 (dm2ws) undefined - undefined 2'b11 - (both WKUP_TIMEOUT1 and WKUP_TIMEOUT0)
{0x5100+4i} CFG0_CLAIMREG_P1_R{i}_READONLY ro (i=0..14)
  [31:0] CLAIMREG_P1_R{i}_READONLY — Claim bits for Partition 1
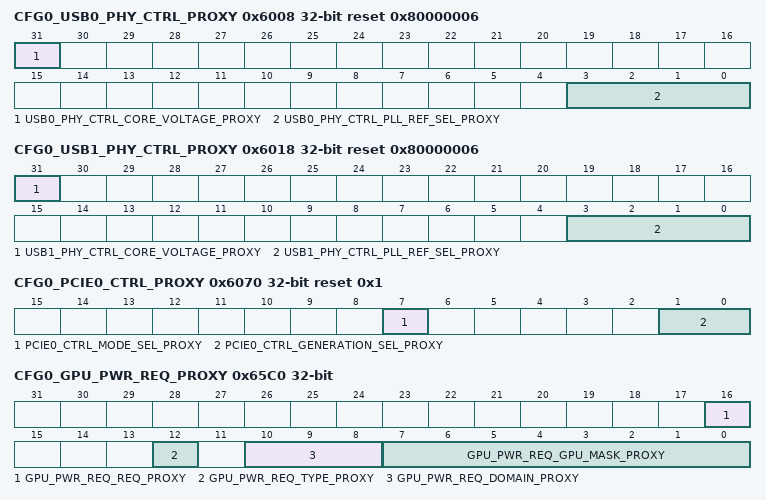
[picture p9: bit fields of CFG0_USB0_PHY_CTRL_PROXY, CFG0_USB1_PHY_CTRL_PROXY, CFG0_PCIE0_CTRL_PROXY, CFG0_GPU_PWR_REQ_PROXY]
0x6008 CFG0_USB0_PHY_CTRL_PROXY reset 0x80000006
  [31] USB0_PHY_CTRL_CORE_VOLTAGE_PROXY — Selects the USB PHY Core Voltage Option: 0.85V or 0.75/0.80V Field values (others are reserved): 1'b0 - V_0P85 1'b1 - V_0P75_0P80
  [3:0] USB0_PHY_CTRL_PLL_REF_SEL_PROXY — Indicates the frequency of the REF_CLOCK input used by the USB PLL. This value should be set to match the frequency of the USB0 input clock, as selected by the USB0_CLKSEL register Field values (others are reserved): 4'b0000 - MHZ_9P6 4'b0001 - MHZ_10 4'b0010 - MHZ_12 4'b0011 - MHZ_19P2 4'b0100 - MHZ_20 4'b0101 - MHZ_24 4'b0110 - MHZ_25 4'b0111 - MHZ_26 4'b1000 - MHZ_38P4 4'b1001 - MHZ_40 4'b1010 - MHZ_48 4'b1011 - MHZ_50 4'b1100 - MHZ_52
0x6018 CFG0_USB1_PHY_CTRL_PROXY reset 0x80000006
  [31] USB1_PHY_CTRL_CORE_VOLTAGE_PROXY — Selects the USB PHY Core Voltage Option: 0.85V or 0.75/0.80V Field values (others are reserved): 1'b0 - V_0P85 1'b1 - V_0P75_0P80
  [3:0] USB1_PHY_CTRL_PLL_REF_SEL_PROXY — Indicates the frequency of the REF_CLOCK input used by the USB PLL. This value should be set to match the frequency of the USB1 input clock, as selected by the USB1_CLKSEL register Field values (others are reserved): 4'b0000 - MHZ_9P6 4'b0001 - MHZ_10 4'b0010 - MHZ_12 4'b0011 - MHZ_19P2 4'b0100 - MHZ_20 4'b0101 - MHZ_24 4'b0110 - MHZ_25 4'b0111 - MHZ_26 4'b1000 - MHZ_38P4 4'b1001 - MHZ_40 4'b1010 - MHZ_48 4'b1011 - MHZ_50 4'b1100 - MHZ_52
0x6070 CFG0_PCIE0_CTRL_PROXY reset 0x1
  [7] PCIE0_CTRL_MODE_SEL_PROXY — Selects the operating mode Field values (others are reserved): 1'b0 - ENDPOINT 1'b1 - ROOT_COMPLEX
  [1:0] PCIE0_CTRL_GENERATION_SEL_PROXY — Configures the PCIe generation support in the PCIe capabilities linked-list Field values (others are reserved): 2'b00 - GEN1 2'b01 - GEN2 2'b10 - GEN3
{0x61B4+4i} CFG0_SDIO{i}_CTRL_PROXY (i=0..2)
  [4:0] SDIO{i}_CTRL_DRV_STR_PROXY — Selects the SDIO drive strength Note: Values other than the reset value may invalidate the datasheet timing parameters and therefore should not be used.. Default is an efuse trimmed value, trimmed to aproximately 40 Ohms. Expected values for trim are between DS_10 and DS_19. Changing the value of this field is not recommended. Field values (others are reserved): 5'b11111 - DS_31 (MAX) 5'b11110 - DS_30 5'b11101 - DS_29 5'b11100 - DS_28 5'b11011 - DS_27 5'b11010 - DS_26 5'b11001 - DS_25 5'b11000 - DS_24 5'b10111 - DS_23 5'b10110 - DS_22 5'b10101 - DS_21 5'b10100 - DS_20 5'b10011 - DS_19 5'b10010 - DS_18 5'b10001 - DS_17 5'b10000 - DS_16 5'b01111 - DS_15 5'b01110 - DS_14 5'b01101 - DS_13 5'b01100 - DS_12 5'b01011 - DS_11 5'b01010 - DS_10 5'b01001 - DS_9 5'b01000 - DS_8 5'b00111 - DS_7 5'b00110 - DS_6 5'b00101 - DS_5 5'b00100 - DS_4 5'b00011 - DS_3 5'b00010 - DS_2 5'b00001 - DS_1 5'b00000 - DS_0 (MIN)
0x6204 CFG0_WKUP_TIMER1_CTRL_PROXY
  [8] WKUP_TIMER1_CTRL_CASCADE_EN_PROXY — Activates cascading of TIMER1 to TIMER0 Field values (others are reserved): 1'b0 - CASCADE_DEACTIVATED 1'b1 - CASCADE_ACTIVATED
0x62E0 CFG0_WKUP_I2C0_CTRL_PROXY
  [0] WKUP_I2C0_CTRL_HS_MCS_EN_PROXY — HS Mode controller current source activate. When set, activates the current-source pull-up on the SCL output. Only one controller on the I2C bus should activate SCL current sourcing. Field values (others are reserved): 1'b0 - HS_MCS_INACTIVE 1'b1 - HS_MCS_ACTIVE
0x65C0 CFG0_GPU_PWR_REQ_PROXY ro
  [16] GPU_PWR_REQ_REQ_PROXY — Power control request. This bit is set by the GPU to request a Power Management event to the PM processor. This will generate a gpu0_pwr_req interrupt. The interrupt is cleared only when the GPU clears its pwrctrl_gpu_req output. Field values (others are reserved): 1'b0 - CLEARED 1'b1 - POWER_REQ_ACTIVE
  [12] GPU_PWR_REQ_TYPE_PROXY — GPU request type. Field values (others are reserved): 1'b0 - POWER_DOWN_REQ 1'b1 - POWER_UP_REQ
  [10:8] GPU_PWR_REQ_DOMAIN_PROXY — GPU request mask. Indicates GPU domain to which the power event applies. For mapping refer to GPU RGX_CR_POWER_EVENT register.
  [7:0] GPU_PWR_REQ_GPU_MASK_PROXY — GPU request mask. One bit per GPU indicating to which GPUs the power event applies. Mask bits are indexed by GPU_ID
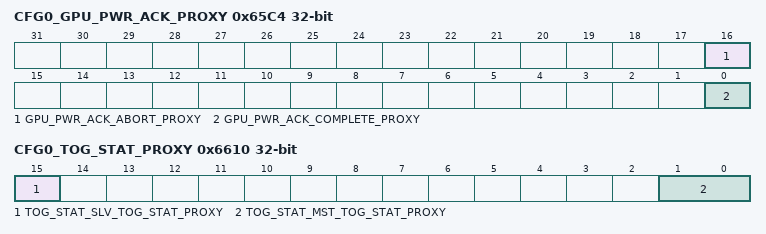
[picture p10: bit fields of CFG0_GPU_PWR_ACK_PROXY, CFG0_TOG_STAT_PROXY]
0x65C4 CFG0_GPU_PWR_ACK_PROXY
  [16] GPU_PWR_ACK_ABORT_PROXY — Power control exit. This bit is set by the PM processor to that the GPU power control request could not be completed. The bit is cleared to 0 when gpu0_pwr_req goes low. Field values (others are reserved): 1'b0 - CLEARED 1'b1 - ERROR_NOT_COMPLETED
  [0] GPU_PWR_ACK_COMPLETE_PROXY — Power control complete. This bit is set by the PM processor to indicate sucessful completion of the GPU power control request. The bit is cleared to 0 when gpu0_pwr_req goes low. Field values (others are reserved): 1'b0 - CLEARED 1'b1 - COMPLETE
0x6610 CFG0_TOG_STAT_PROXY ro
  [15] TOG_STAT_SLV_TOG_STAT_PROXY — Error Status of Target Timeout Gaskets Field values (others are reserved): 1'b0 - NONE 1'b1 - MCU_TIMEOUT0 (mcu2dm)
  [1:0] TOG_STAT_MST_TOG_STAT_PROXY — Error Status of Target Timeout Gaskets Field values (others are reserved): 2'b00 - NONE 2'b01 - WKUP_TIMEOUT1 (dm2mcu) undefined - undefined 2'b10 - WKUP_TIMEOUT0 (dm2ws) undefined - undefined 2'b11 - (both WKUP_TIMEOUT1 and WKUP_TIMEOUT0)
